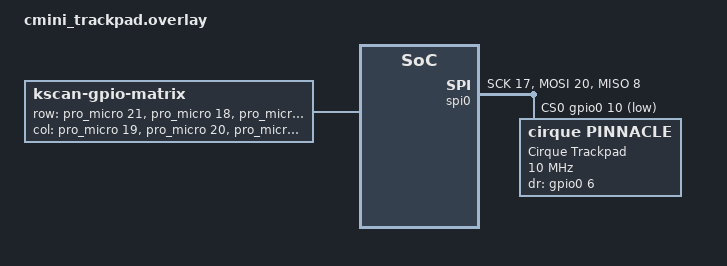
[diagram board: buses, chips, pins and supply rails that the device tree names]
#include "cmini.dtsi" // Notice that the main dtsi files are included in the overlay.


/ {
    kscan0: kscan {
        compatible = "zmk,kscan-gpio-matrix";
        label = "KSCAN";
        diode-direction = "col2row";

        row-gpios
        = <&pro_micro 21 (GPIO_ACTIVE_HIGH | GPIO_PULL_DOWN)>
        , <&pro_micro 18 (GPIO_ACTIVE_HIGH | GPIO_PULL_DOWN)>
        , <&pro_micro 5 (GPIO_ACTIVE_HIGH | GPIO_PULL_DOWN)>
        , <&pro_micro 4 (GPIO_ACTIVE_HIGH | GPIO_PULL_DOWN)>
        ;
    col-gpios
        = <&pro_micro 19 GPIO_ACTIVE_HIGH>
        , <&pro_micro 20 GPIO_ACTIVE_HIGH>
        , <&pro_micro 10 GPIO_ACTIVE_HIGH>
        , <&pro_micro 6 GPIO_ACTIVE_HIGH>
        , <&pro_micro 7 GPIO_ACTIVE_HIGH>
        , <&pro_micro 8 GPIO_ACTIVE_HIGH>
        ;
    };
};

&spi0 {
    compatible = "nordic,nrf-spim";
    status = "okay";
    miso-pin = <8>; // P0.08
    mosi-pin = <20>; // should not be used 
    sck-pin = <17>; // P0.17
    cs-gpios = <&gpio0 10 GPIO_ACTIVE_LOW>; // P0.06

    trackpad@0 {
        compatible = "cirque,pinnacle";
        status = "okay";
        reg = <0>;
        label = "Cirque Trackpad";
        spi-max-frequency = <10000000>;
        dr-gpios = <&gpio0 6 GPIO_ACTIVE_HIGH>;
        invert-x;
        sleep;
        /* no-taps; */
    };
};
